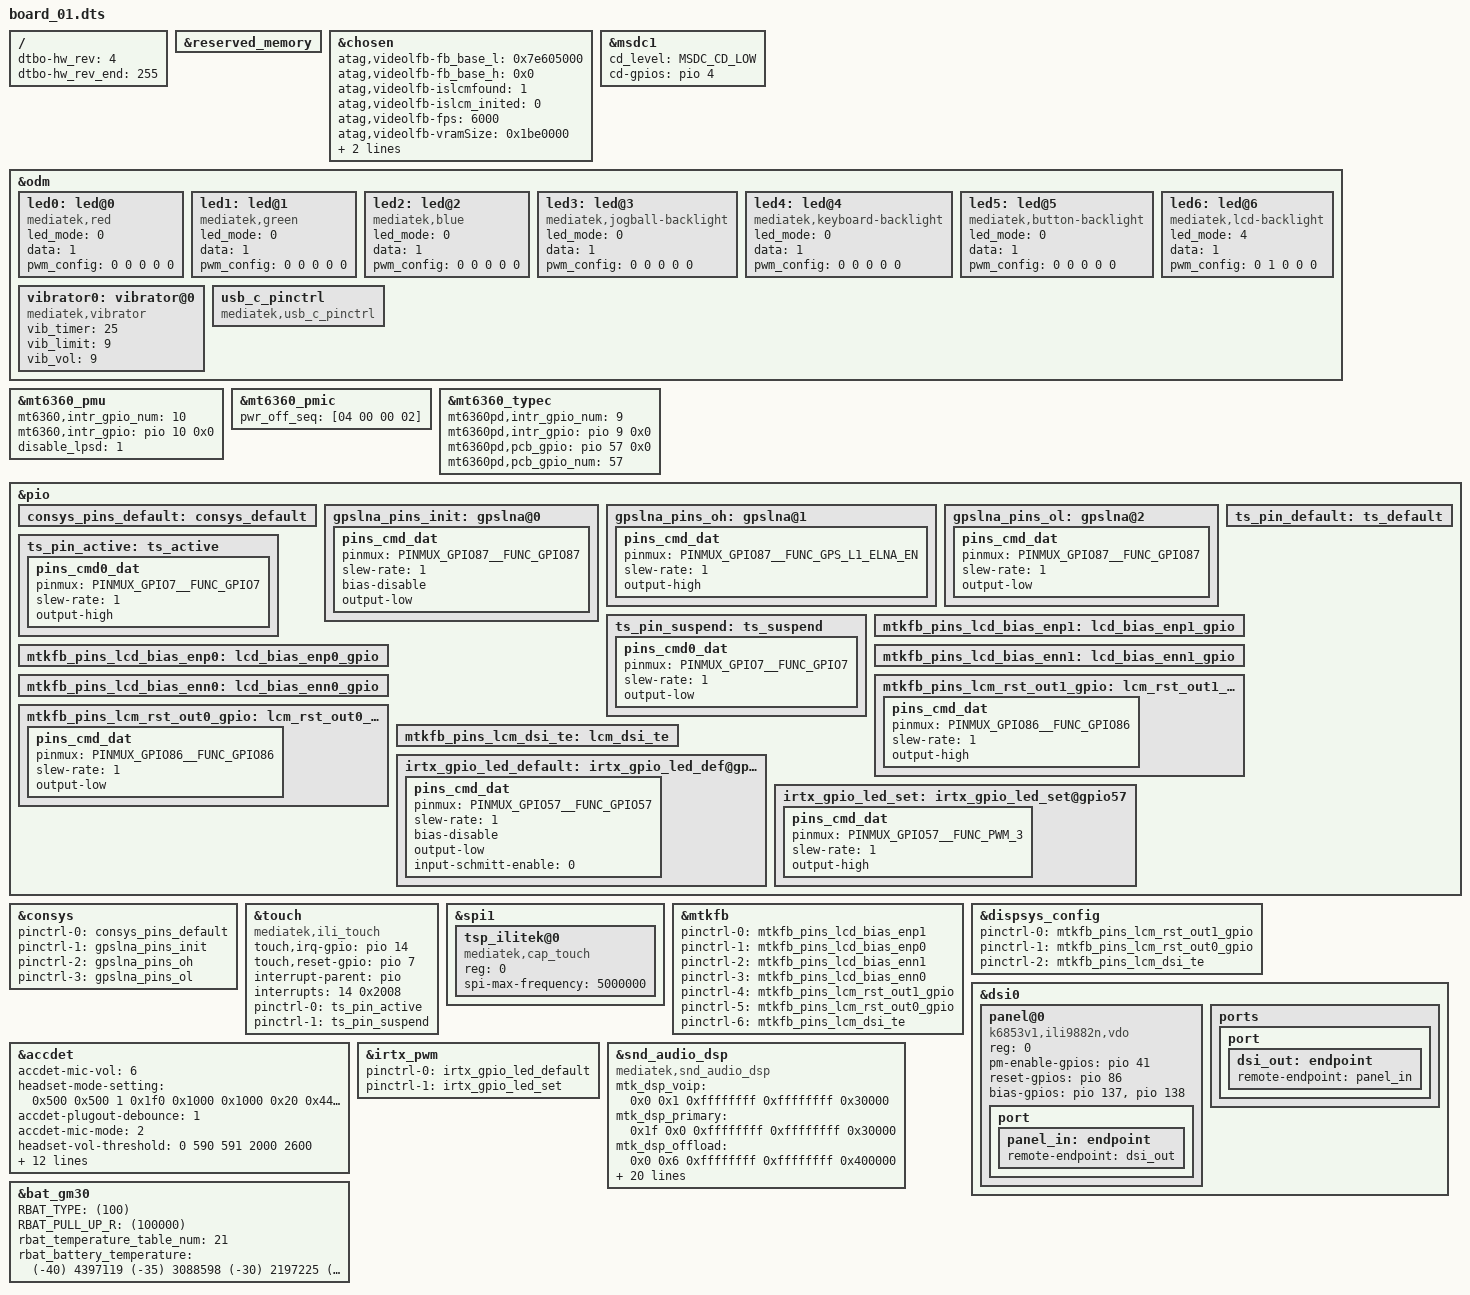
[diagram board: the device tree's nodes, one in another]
/*
 * Mediatek's mt6853 SoC device tree source
 *
 * Copyright (C) 2016 MediaTek Inc.
 *
 * This program is free software; you can redistribute it and/or modify
 * it under the terms of the GNU General Public License version 2 as
 * published by the Free Software Foundation.
 *
 * This program is distributed in the hope that it will be useful,
 * but WITHOUT ANY WARRANTY; without even the implied warranty of
 * MERCHANTABILITY or FITNESS FOR A PARTICULAR PURPOSE.
 * See http://www.gnu.org/licenses/gpl-2.0.html for more details.
 */
/dts-v1/;
/plugin/;
#include <dt-bindings/interrupt-controller/irq.h>
#include <dt-bindings/interrupt-controller/arm-gic.h>
#include <dt-bindings/pinctrl/mt6853-pinfunc.h>
#include <dt-bindings/mmc/mt6853-msdc.h>
#include <generated/autoconf.h>

/ {
	fragment@model {
		target-path = "/";
		__overlay__ {
			dtbo-hw_rev = <4>;
			dtbo-hw_rev_end = <255>;
		};
	};
};

&reserved_memory {
};

/* chosen */
&chosen {

	atag,videolfb-fb_base_l = <0x7e605000>;
	atag,videolfb-fb_base_h = <0x0>;
	atag,videolfb-islcmfound = <1>;
	atag,videolfb-islcm_inited = <0>;
	atag,videolfb-fps= <6000>;
	atag,videolfb-vramSize= <0x1be0000>;
	atag,videolfb-lcmname=
		"nt35595_fhd_dsi_cmd_truly_nt50358_drv";
};

/* MSDC1 */
&msdc1 {
	cd_level = /bits/ 8 <MSDC_CD_LOW>;
	cd-gpios = <&pio 4 0>;
};
/* MSDC1 */

&odm {
	led0:led@0 {
		compatible = "mediatek,red";
		led_mode = <0>;
		data = <1>;
		pwm_config = <0 0 0 0 0>;
	};
	led1:led@1 {
		compatible = "mediatek,green";
		led_mode = <0>;
		data = <1>;
		pwm_config = <0 0 0 0 0>;
	};
	led2:led@2 {
		compatible = "mediatek,blue";
		led_mode = <0>;
		data = <1>;
		pwm_config = <0 0 0 0 0>;
	};
	led3:led@3 {
		compatible = "mediatek,jogball-backlight";
		led_mode = <0>;
		data = <1>;
		pwm_config = <0 0 0 0 0>;
	};
	led4:led@4 {
		compatible = "mediatek,keyboard-backlight";
		led_mode = <0>;
		data = <1>;
		pwm_config = <0 0 0 0 0>;
	};
	led5:led@5 {
		compatible = "mediatek,button-backlight";
		led_mode = <0>;
		data = <1>;
		pwm_config = <0 0 0 0 0>;
	};
	led6:led@6 {
		compatible = "mediatek,lcd-backlight";
		led_mode = <4>;
		data = <1>;
		pwm_config = <0 1 0 0 0>;
	};
	vibrator0:vibrator@0 {
		compatible = "mediatek,vibrator";
		vib_timer = <25>;
		vib_limit = <9>;
		vib_vol= <9>;
	};
	usb_c_pinctrl:usb_c_pinctrl {
		compatible = "mediatek,usb_c_pinctrl";
	};
};

&mt6360_pmu {
	mt6360,intr_gpio_num = <10>; /* direct defined GPIO num */
	mt6360,intr_gpio = <&pio 10 0x0>;
	disable_lpsd = <1>;
};

&mt6360_pmic {
	pwr_off_seq = [04 00 00 02];
};

&mt6360_typec {
	mt6360pd,intr_gpio_num = <9>; /* direct defined GPIO num */
	mt6360pd,intr_gpio = <&pio 9 0x0>;
	mt6360pd,pcb_gpio = <&pio 57 0x0>;
	mt6360pd,pcb_gpio_num = <57>;
};

/* CONSYS GPIO standardization */
&pio {
	consys_pins_default: consys_default {
	};
	gpslna_pins_init: gpslna@0 {
		pins_cmd_dat {
			pinmux = <PINMUX_GPIO87__FUNC_GPIO87>;
			slew-rate = <1>;
			bias-disable;
			output-low;
		};
	};
	gpslna_pins_oh: gpslna@1 {
		pins_cmd_dat {
			pinmux = <PINMUX_GPIO87__FUNC_GPS_L1_ELNA_EN>;
			slew-rate = <1>;
			output-high;
		};
	};
	gpslna_pins_ol: gpslna@2 {
		pins_cmd_dat {
			pinmux = <PINMUX_GPIO87__FUNC_GPIO87>;
			slew-rate = <1>;
			output-low;
		};
	};
};

&consys {
	pinctrl-names = "default", "gps_lna_state_init",
		"gps_lna_state_oh", "gps_lna_state_ol";
	pinctrl-0 = <&consys_pins_default>;
	pinctrl-1 = <&gpslna_pins_init>;
	pinctrl-2 = <&gpslna_pins_oh>;
	pinctrl-3 = <&gpslna_pins_ol>;
	status = "okay";
};
/* CONSYS end */

/* TOUCH start */
&touch {
	compatible = "mediatek,ili_touch";
	/* IRQF_ONESHOT | IRQF_TRIGGER_LOW */
	touch,irq-gpio = <&pio 14 0x2008>;
	touch,reset-gpio = <&pio 7 0x2008>;
	interrupt-parent = <&pio>;
	interrupts = <14 0x2008>;
	/* vdd-supply = <&pm8994_lvs2>; */
	/* avdd-supply = <&pm8994_l22>; */
	pinctrl-names = "pmx_ts_active", "pmx_ts_suspend";
	pinctrl-0 = <&ts_pin_active>;
	pinctrl-1 = <&ts_pin_suspend>;
};

&spi1 {
	status = "okay";

	#address-cells = <1>;
	#size-cells = <0>;

	tsp_ilitek@0 {
		compatible = "mediatek,cap_touch";
		reg = <0>;
		spi-max-frequency = <5000000>;
	};
};

/* touch gpio start */
&pio {
	ts_pin_default: ts_default {
	};

	ts_pin_active: ts_active {
		pins_cmd0_dat {
			pinmux = <PINMUX_GPIO7__FUNC_GPIO7>;
			slew-rate = <1>;
			output-high;
		};
	};

	ts_pin_suspend: ts_suspend {
		pins_cmd0_dat {
			pinmux = <PINMUX_GPIO7__FUNC_GPIO7>;
			slew-rate = <1>;
			output-low;
		};
	};
};
/* touch gpio end */
/* TOUCH end */

#include "mediatek/k6853v1_64_titan/camera01.dtsi"
#include "mediatek/k6853v1_64_titan/gpio01.dtsi"
/* DISPSYS GPIO standardization */

#ifndef CONFIG_FPGA_EARLY_PORTING
&pio {
	mtkfb_pins_lcd_bias_enp1: lcd_bias_enp1_gpio {
	};

	mtkfb_pins_lcd_bias_enp0: lcd_bias_enp0_gpio {
	};

	mtkfb_pins_lcd_bias_enn1: lcd_bias_enn1_gpio {
	};

	mtkfb_pins_lcd_bias_enn0: lcd_bias_enn0_gpio {
	};

	mtkfb_pins_lcm_rst_out1_gpio: lcm_rst_out1_gpio {
		pins_cmd_dat {
			pinmux = <PINMUX_GPIO86__FUNC_GPIO86>;
			slew-rate = <1>;
			output-high;
		};
	};

	mtkfb_pins_lcm_rst_out0_gpio: lcm_rst_out0_gpio {
		pins_cmd_dat {
			pinmux = <PINMUX_GPIO86__FUNC_GPIO86>;
			slew-rate = <1>;
			output-low;
		};
	};
	mtkfb_pins_lcm_dsi_te: lcm_dsi_te {
	};
};

&mtkfb {
	pinctrl-names = "lcd_bias_enp1_gpio", "lcd_bias_enp0_gpio",
		"lcd_bias_enn1_gpio", "lcd_bias_enn0_gpio",
		"lcm_rst_out1_gpio", "lcm_rst_out0_gpio",
		"mode_te_te";
	pinctrl-0 = <&mtkfb_pins_lcd_bias_enp1>;
	pinctrl-1 = <&mtkfb_pins_lcd_bias_enp0>;
	pinctrl-2 = <&mtkfb_pins_lcd_bias_enn1>;
	pinctrl-3 = <&mtkfb_pins_lcd_bias_enn0>;
	pinctrl-4 = <&mtkfb_pins_lcm_rst_out1_gpio>;
	pinctrl-5 = <&mtkfb_pins_lcm_rst_out0_gpio>;
	pinctrl-6 = <&mtkfb_pins_lcm_dsi_te>;
	status = "okay";
};
&dispsys_config {
	pinctrl-names =
		"lcm_rst_out1_gpio", "lcm_rst_out0_gpio",
		"mode_te_te";
	pinctrl-0 = <&mtkfb_pins_lcm_rst_out1_gpio>;
	pinctrl-1 = <&mtkfb_pins_lcm_rst_out0_gpio>;
	pinctrl-2 = <&mtkfb_pins_lcm_dsi_te>;
	status = "okay";
};
&dsi0 {
	status = "okay";
	#address-cells = <1>;
	#size-cells = <0>;
	panel@0 {
		compatible = "k6853v1,ili9882n,vdo";
		reg = <0>;
		pm-enable-gpios = <&pio 41 0>;
		reset-gpios = <&pio 86 0>;
		bias-gpios = <&pio 137 0>,
			<&pio 138 0>;
		pinctrl-names = "default";
		port {
			panel_in: endpoint {
				remote-endpoint = <&dsi_out>;
			};
		};
	};
	ports {
		port {
			dsi_out: endpoint {
				remote-endpoint = <&panel_in>;
			};
		};
	};
};

/* accdet start */
&accdet {
	/* accdet micbias voltage: 0x09:2.85v 0x08:2.8v 0x07,
	 * 2.7v;0x05,2.5v;0x02,1.9v
	 */
	accdet-mic-vol = <6>;
	/* accdet pwm_width, pwm_thresh, fall_delay, rise_delay
	 * debounce0, debounce1, debounce3, debounce4
	 * eint pwm_width, eint pwm_thresh
	 * eint deb(debounce0, debounce1, debounce2, debounce3), inv_debounce
	 */
	headset-mode-setting = <0x500 0x500 1 0x1f0
				0x1000 0x1000 0x20 0x44
				0x4 0x1
				0xe 0x3 0x3 0x5 0xe>;
	accdet-plugout-debounce = <1>;
	/*1:ACC mode, 2:low cost without in bias, 6:low cost with in bias*/
	accdet-mic-mode = <2>;
	/*min_3pole--max_3pole--min_4pole--max_4pole--vol_bias*/
	headset-vol-threshold = <0 590 591 2000 2600>;
	/*0--MD_MAX--UP_MAX--DW_MAX*/
	headset-three-key-threshold = <0 80 220 400>;
	headset-three-key-threshold-CDD = <0 121 192 600>;
	/*0--MD_MAX--VOICE_MAX--UP_MAX--DW_MAX*/
	headset-four-key-threshold = <0 83 115 189 400>;

	moisture_detect_enable = <1>;
	moisture_detect_mode = <1>;
	eint_detect_mode = <1>;
	/* use external resitance */
	eint_use_ext_res = <1>;
	/* select VTH to 2v, 0:2.8V,1:2.4V,2:2V */
	eint_comp_vth = <2>;

	/* moisture SW mode config start, use external resister or not.
	 */
	moisture-ver = <1>;
	moisture_use_ext_res = <1>;
	/* moisture of water resister ohm, SW mode by auxadc*/
	moisture-water-r = <50000>;
	moisture-vm = <100>;
	/* moisture SW mode config end */

	status = "okay";
};
/* accdet end */

/* IRTX GPIO Start */
&irtx_pwm {
	pinctrl-names = "irtx_gpio_led_default", "irtx_gpio_led_set";
	pinctrl-0 = <&irtx_gpio_led_default>;
	pinctrl-1 = <&irtx_gpio_led_set>;
	status = "okay";
};
&pio {
	/* IRTX GPIO Settings -Start */
	/* default: GPIO0, output, high */
	irtx_gpio_led_default:irtx_gpio_led_def@gpio57 {
		pins_cmd_dat {
			pinmux = <PINMUX_GPIO57__FUNC_GPIO57>;
			slew-rate = <1>;
			bias-disable;
			output-low;
			input-schmitt-enable = <0>;
		};
	};

	irtx_gpio_led_set:irtx_gpio_led_set@gpio57 {
		pins_cmd_dat {
			pinmux = <PINMUX_GPIO57__FUNC_PWM_3>;
			slew-rate = <1>;
			output-high;
		};
	};
}; /* IRTX GPIO Settings -End */

/* Audio AMP Start */

&snd_audio_dsp {
	compatible = "mediatek,snd_audio_dsp";
	mtk_dsp_voip = <0x0 0x1 0xffffffff 0xffffffff 0x30000>;
	mtk_dsp_primary = <0x1f 0x0 0xffffffff 0xffffffff 0x30000>;
	mtk_dsp_offload = <0x0 0x6 0xffffffff 0xffffffff 0x400000>;
	mtk_dsp_deep = <0x5 0x3 0xffffffff 0xffffffff 0x30000>;
	mtk_dsp_playback = <0x1 0x4 0x10 0x14 0x30000>;
	mtk_dsp_music = <0x1 0xffffffff 0xffffffff 0xffffffff 0x0>;
	mtk_dsp_capture1 = <0x1 0xffffffff 0xd 0x13 0x20000>;
	mtk_dsp_a2dp = <0x0 0xffffffff 0xffffffff 0xffffffff 0x40000>;
	mtk_dsp_dataprovider = <0x0 0xffffffff 0xf 0xffffffff 0x30000>;
	mtk_dsp_call_final = <0x5 0x0 0x10 0x14 0x18000>;
	mtk_dsp_fast = <0x5 0x2 0xffffffff 0xffffffff 0x5000>;
	mtk_dsp_ktv = <0x0 0x8 0x12 0xffffffff 0x10000>;
	mtk_dsp_capture_raw = <0x0 0xffffffff 0xffffffff 0xffffffff 0x20000>;
	mtk_dsp_ver = <0x1>;
	swdsp_smartpa_process_enable = <0x5>;
	mtk_dsp_mem_afe = <0x1 0x40000>; /* always enable */
};
/* Audio AMP -End*/

&bat_gm30 {
	/* battery temperature table type - NTC table */
	RBAT_TYPE = <(100)>;
	RBAT_PULL_UP_R = <(100000)>;

	rbat_temperature_table_num = <21>;
	rbat_battery_temperature =
	<
		(-40) 4397119
		(-35) 3088598
		(-30) 2197225
		(-25) 1581880
		(-20) 1151036
		(-15) 846578
		(-10) 628988
		(-5) 471632
		0 357011
		5 272499
		10 209709
		15 162650
		20 127080
		25 100000
		30 79221
		35 63167
		40 50676
		45 40903
		50 33194
		55 27090
		60 22224 >;
};

#endif
/*End of this file, DO NOT ADD ANYTHING HERE*/

